# earlgrey register map
Vendor: lowRISC; File version: 0.1
CPU: ibex rev01, little endian, no MPU, no FPU, VTOR, 2 interrupt priority bits, 2 interrupts
Registers are 32-bit, read-write, no defined reset value unless marked. A register's access mark holds for its fields unless they carry their own. Offsets are from the block's base; [hi:lo] are bit positions; {n}, {i} and the like mark numbered series.

## AES — AES encryption and decryption engine with SCA and FI countermeasures
Base 0x41100000
{0x40+4i} KEY_SHARE0_{i} wo (i=0..7) — Initial Key Registers Share 0.The actual initial key corresponds to Initial Key Registers Share 0 XORed with Initial Key Registers Share 1.Loaded into the internal Full Key register upon starting encryption/decryption of the next block.All key registers (Share 0 and Share 1) must be written at least once when the key is changed, regardless of key length (write random data for unused bits).The order in which the registers are updated does not matter.Can only be updated when the AES unit is idle.If the AES unit is non-idle, writes to these registers are ignored.Upon reset, these registers are cleared with pseudo-random data.
  [31:0] key_share0_{i} — Initial Key Share 0
{0x60+4i} KEY_SHARE1_{i} wo (i=0..7) — Initial Key Registers Share 1.The actual initial key corresponds to Initial Key Registers Share 0 XORed with Initial Key Registers Share 1.Loaded into the internal Full Key register upon starting encryption/decryption of the next block.All key registers (Share 0 and Share 1) must be written at least once when the key is changed, regardless of key length (write random data for unused bits).The order in which the registers are updated does not matter.Can only be updated when the AES unit is idle.If the AES unit is non-idle, writes to these registers are ignored.Upon reset, these registers are cleared with pseudo-random data.
  [31:0] key_share1_{i} — Initial Key Share 1
{0x80+4i} IV_{i} (i=0..3) — Initialization Vector Registers.The initialization vector (IV) or initial counter value must be written to these registers when starting a new message in CBC or CTR mode (see Control Register), respectively.In CBC and CTR modes, the AES unit does not start encryption/decryption with a partially updated IV.Each register has to be written at least once.The order in which the registers are written does not matter.If the AES unit is non-idle, writes to these registers are ignored.Whenever starting a new message, the corresponding IV value must be provided by the processor.Once started, the AES unit automatically updates the contents of these registers.In ECB mode, the IV registers are not used and do not need to be configured.Upon reset, these registers are cleared with pseudo-random data.
  [31:0] iv_{i} — Initialization Vector
{0x90+4i} DATA_IN_{i} wo (i=0..3) — Input Data Registers.If MANUAL_OPERATION=0 (see Control Register), the AES unit automatically starts encryption/decryption after all Input Data registers have been written.Each register has to be written at least once.The order in which the registers are written does not matter.Loaded into the internal State register upon starting encryption/decryption of the next block.After that, the processor can update the Input Data registers (See INPUT_READY field of Status Register).Upon reset, these registers are cleared with pseudo-random data.
  [31:0] data_in_{i} — Input Data
{0xA0+4i} DATA_OUT_{i} ro (i=0..3) — Output Data Register.Holds the output data produced by the AES unit during the last encryption/decryption operation.If MANUAL_OPERATION=0 (see Control Register), the AES unit is stalled when the previous output data has not yet been read and is about to be overwritten.Each register has to be read at least once.The order in which the registers are read does not matter.Upon reset, these registers are cleared with pseudo-random data.
  [31:0] data_out_{i} — Output Data
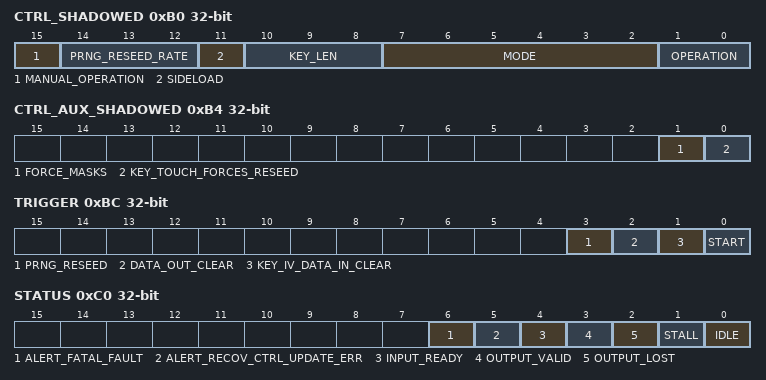
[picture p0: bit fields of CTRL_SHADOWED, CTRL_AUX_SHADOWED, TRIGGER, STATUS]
0xB0 CTRL_SHADOWED — Control Register.Can only be updated when the AES unit is idle.If the AES unit is non-idle, writes to this register are ignored.This register is shadowed, meaning two subsequent write operations are required to change its content.If the two write operations try to set a different value, a recoverable alert is triggered (See Status Register).A read operation clears the internal phase tracking: The next write operation is always considered a first write operation of an update sequence.Any write operation to this register will clear the status tracking required for automatic mode (See MANUAL_OPERATION field).A write to the Control Register is considered the start of a new message.Hence, software needs to provide new key, IV and input data afterwards.
  [15] MANUAL_OPERATION — Controls whether the AES unit is operated in normal/automatic mode (0) or fully manual mode (1).In automatic mode (0), the AES unit automatically i) starts to encrypt/decrypt when it receives new input data, and ii) stalls during the last encryption/decryption cycle if the previous output data has not yet been read.This is the most efficient mode to operate in.Note that the corresponding status tracking is automatically cleared upon a write to the Control Register.In manual mode (1), the AES unit i) only starts to encrypt/decrypt after receiving a start trigger (see Trigger Register), and ii) overwrites previous output data irrespective of whether it has been read out or not.This mode is useful if software needs full control over the AES unit.
  [14:12] PRNG_RESEED_RATE — 3-bit one-hot field to control the reseeding rate of the internal pseudo-random number generator (PRNG) used for masking.Invalid input values, i.e., values with multiple bits set and value 3'b000 are mapped to the highest reseeding rate PER_1 (3'b001).
  [11] SIDELOAD — Controls whether the AES unit uses the key provided by the key manager via key sideload interface (1) or the key provided by software via Initial Key Registers KEY_SHARE1_0 - KEY_SHARE1_7 (0).
  [10:8] KEY_LEN — 3-bit one-hot field to select AES key length.Invalid input values, i.e., values with multiple bits set, value 3'b000, and value 3'b010 in case 192-bit keys are not supported (because disabled at compile time) are mapped to AES_256 (3'b100).
  [7:2] MODE — 6-bit one-hot field to select AES block cipher mode.Invalid input values, i.e., values with multiple bits set and value 6'b00_0000, are mapped to AES_NONE (6'b10_0000).
  [1:0] OPERATION — 2-bit one-hot field to select the operation of AES unit.Invalid input values, i.e., values with multiple bits set and value 2'b00, are mapped to AES_ENC (2'b01).
0xB4 CTRL_AUX_SHADOWED — Auxiliary Control Register.This register is shadowed, meaning two subsequent write operations are required to change its content.If the two write operations try to set a different value, a recoverable alert is triggered (See Status Register).A read operation clears the internal phase tracking: The next write operation is always considered a first write operation of an update sequence.
  [1] FORCE_MASKS — Allow the internal masking PRNG to advance (0) or force its internal state (1) leading to constant masks.Setting all masks to constant value can be useful when performing SCA.To completely disable the masking, the second key share (KEY_SHARE1_0 - KEY_SHARE1_7) must be zero as well.In addition, a special seed needs to be loaded into the masking PRNG using the EDN interface.Only applicable if both the Masking parameter and the SecAllowForcingMasks parameter are set to one.
  [0] KEY_TOUCH_FORCES_RESEED — Controls whether providing a new key triggers the reseeding of internal pseudo-random number generators used for clearing and masking (1) or not (0).
0xB8 CTRL_AUX_REGWEN — Lock bit for Auxiliary Control Register.
  [0] Value — Auxiliary Control Register configuration enable bit.If this is cleared to 0, the Auxiliary Control Register cannot be written anymore.
0xBC TRIGGER wo — Trigger Register.Each bit is individually cleared to zero when executing the corresponding trigger.While executing any of the triggered operations, the AES unit will set the IDLE bit in the Status Register to zero.The processor must check the Status Register before triggering further actions.For example, writes to Initial Key and IV Registers are ignored while the AES unit is busy.Writes to the Input Data Registers are not ignored but the data will be cleared if a KEY_IV_DATA_IN_CLEAR operation is pending.
  [3] PRNG_RESEED — Keep continuing with the current states of the internal pseudo-random number generators used for register clearing and masking (0) or perform a reseed of the internal states from the connected entropy source (1).If the KEY_TOUCH_FORCES_RESEED bit in the Auxiliary Control Register is set to one, this trigger will automatically get set after providing a new initial key.
  [2] DATA_OUT_CLEAR — Keep current values in Output Data registers (0) or clear those registers with pseudo-random data (1).
  [1] KEY_IV_DATA_IN_CLEAR — Keep current values in Initial Key, internal Full Key and Decryption Key registers, IV registers and Input Data registers (0) or clear all those registers with pseudo-random data (1).
  [0] START — Keep AES unit paused (0) or trigger the encryption/decryption of one data block (1).This trigger is cleared to `0` if MANUAL_OPERATION=0 or if MODE=AES_NONE (see Control Register).
0xC0 STATUS ro
  [6] ALERT_FATAL_FAULT — No fatal fault has occurred inside the AES unit (0).A fatal fault has occurred and the AES unit needs to be reset (1).Examples for fatal faults includei) storage errors in the Control Register,ii) if any internal FSM enters an invalid state,iii) if any sparsely encoded signal takes on an invalid value,iv) errors in the internal round counter,v) escalations triggered by the life cycle controller, andvi) fatal integrity failures on the TL-UL bus.
  [5] ALERT_RECOV_CTRL_UPDATE_ERR — An update error has not occurred (0) or has occurred (1) in the shadowed Control Register.AES operation needs to be restarted by re-writing the Control Register.
  [4] INPUT_READY — The AES unit is ready (1) or not ready (0) to receive new data input via the DATA_IN registers.If the present values in the DATA_IN registers have not yet been loaded into themodule this flag is `0` (not ready).
  [3] OUTPUT_VALID — The AES unit has no valid output (0) or has valid output data (1).
  [2] OUTPUT_LOST — All previous output data has been fully read by the processor (0) or at least one previous output data block has been lost (1).It has been overwritten by the AES unit before the processor could fully read it.Once set to `1`, this flag remains set until AES operation is restarted by re-writing the Control Register.The primary use of this flag is for design verification.This flag is not meaningful if MANUAL_OPERATION=0 (see Control Register).
  [1] STALL — The AES unit is not stalled (0) or stalled (1) because there is previousoutput data that must be read by the processor before the AES unit canoverwrite this data.This flag is not meaningful if MANUAL_OPERATION=1 (see Control Register).
  [0] IDLE — The AES unit is idle (1) or busy (0).This flag is `0` if one of the following operations is currently running: i) encryption/decryption, ii) register clearing or iii) PRNG reseeding.This flag is also `0` if an encryption/decryption is running but the AES unit is stalled.
